# MKV56F24 register map
Vendor: Freescale Semiconductor, Inc.; Series: Kinetis_V; File version: 1.6
CPU: CM7 r0p1, little endian, no MPU, FPU, VTOR, 4 interrupt priority bits
Registers are 32-bit, read-write, reset 0x0 unless marked. A register's access mark holds for its fields unless they carry their own. Offsets are from the block's base; [hi:lo] are bit positions; {n}, {i} and the like mark numbered series; 'fields as' and 'values as' point back to an identical list.

## SysTick — System timer
Base 0xE000E010; register names take the prefix SYST_
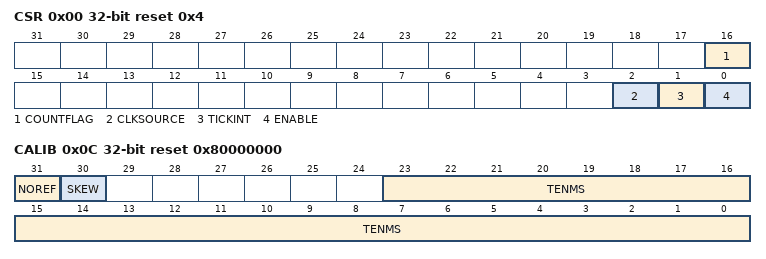
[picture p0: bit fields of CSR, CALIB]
0x00 CSR reset 0x4 — SysTick Control and Status Register
  [16] COUNTFLAG
  [2] CLKSOURCE
    0=external clock; 1=processor clock
  [1] TICKINT
    0=counting down to 0 does not assert the SysTick exception request; 1=counting down to 0 asserts the SysTick exception request
  [0] ENABLE
    0=counter disabled; 1=counter enabled
0x04 RVR — SysTick Reload Value Register
  [23:0] RELOAD — Value to load into the SysTick Current Value Register when the counter reaches 0
0x08 CVR — SysTick Current Value Register
  [23:0] CURRENT — Current value at the time the register is accessed
0x0C CALIB ro reset 0x80000000 — SysTick Calibration Value Register
  [31] NOREF
    0=The reference clock is provided; 1=The reference clock is not provided
  [30] SKEW
    0=10ms calibration value is exact; 1=10ms calibration value is inexact, because of the clock frequency
  [23:0] TENMS — Reload value to use for 10ms timing

## MCM — Core Platform Miscellaneous Control Module
Base 0xE0080000; register names take the prefix MCM_
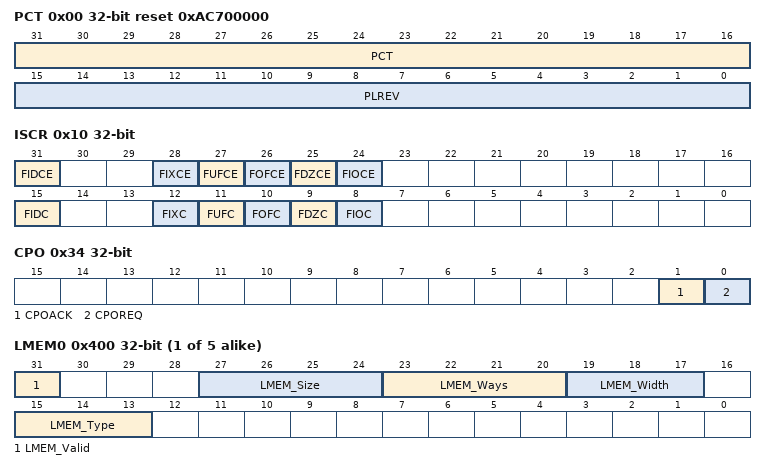
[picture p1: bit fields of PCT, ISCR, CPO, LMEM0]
0x00 PCT ro reset 0xAC700000 — Processor core type
  [31:16] PCT — This MCM design supports the ARM Cortex M7 core.
  [15:0] PLREV — Platform revision
0x0C CR — Control Register
  [27] AHBSPRI — AHB Slave Interface Priority
    0=SW accesses take priority over AHBS accesses; 1=AHBS accesses take priority over SW accesses
0x10 ISCR — Interrupt Status and Control Register
  [31] FIDCE — FPU input denormal interrupt enable
    0=Disable interrupt; 1=Enable interrupt
  [28] FIXCE — FPU inexact interrupt enable
    0=Disable interrupt; 1=Enable interrupt
  [27] FUFCE — FPU underflow interrupt enable
    0=Disable interrupt; 1=Enable interrupt
  [26] FOFCE — FPU overflow interrupt enable
    0=Disable interrupt; 1=Enable interrupt
  [25] FDZCE — FPU divide-by-zero interrupt enable
    0=Disable interrupt; 1=Enable interrupt
  [24] FIOCE — FPU invalid operation interrupt enable
    0=Disable interrupt; 1=Enable interrupt
  [15] FIDC ro — FPU input denormal interrupt status
    0=No interrupt; 1=Interrupt has occured
  [12] FIXC ro — FPU inexact interrupt status
    0=No interrupt; 1=Interrupt has occured
  [11] FUFC ro — FPU underflow interrupt status
    0=No interrupt; 1=Interrupt has occurred
  [10] FOFC ro — FPU overflow interrupt status
    0=No interrupt; 1=Interrupt has occurred
  [9] FDZC ro — FPU divide-by-zero interrupt status
    0=No interrupt; 1=Interrupt has occurred
  [8] FIOC ro — FPU invalid operation interrupt status
    0=No interrupt; 1=Interrupt has occurred
0x34 CPO — Compute Only Operation Control Register
  [1] CPOACK ro — Compute Only Operation acknowledge
    0=Compute only operation entry has not completed or compute only operation exit has completed; 1=Compute only operation entry has completed or compute only operation exit has not completed
  [0] CPOREQ — Compute Only Operation request
    0=Request is cleared; 1=Request Compute Only Operation
{0x400+4i} LMEM{i} (i=0..4) ro — Local Memory General Descriptor Register
  [31] LMEM_Valid — Defines whether the local memory is present
    0=Local memory not present; 1=Local memory present
  [27:24] LMEM_Size — Defines the local memory size
    4=8KB; 5=16KB; 7=64KB
  [23:20] LMEM_Ways — Defines the ways of set associative
    2=2-way set associative; 4=4-way set associative
  [19:17] LMEM_Width — Defines the local memory bit width
    2=32-bits; 3=64-bits
  [15:13] LMEM_Type — Defines the type of local memory
    0=ITCM (Instruction Tightly Coupled Memory); 1=DTCM (Data Tightly Coupled Memory); 2=Instruction Cache; 3=Data Cache

## CAU — Memory Mapped Cryptographic Acceleration Unit (MMCAU)
Base 0xE0081000
{0x0+4i} CAU_DIRECT{i} wo (i=0..15) — Direct access register {i}
  [31:0] CAU_DIRECT{i} — Direct register {i}
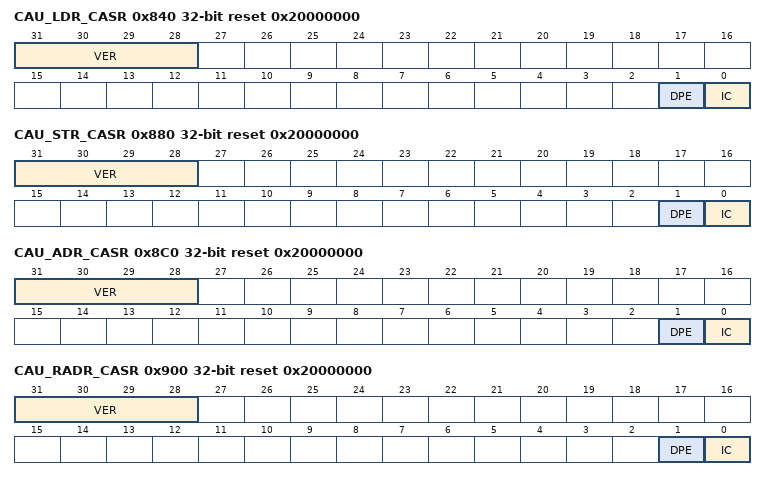
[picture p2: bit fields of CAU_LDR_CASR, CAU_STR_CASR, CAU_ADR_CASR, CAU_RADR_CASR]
0x840 CAU_LDR_CASR wo reset 0x20000000 — Status register - Load Register command
  [31:28] VER — CAU version
    1=Initial CAU version; 2=Second version, added support for SHA-256 algorithm.(This is the value on this device)
  [1] DPE
    0=No error detected; 1=DES key parity error detected
  [0] IC
    0=No illegal commands issued; 1=Illegal command issued
0x844 CAU_LDR_CAA wo — Accumulator register - Load Register command
  [31:0] ACC
{0x848+4i} CAU_LDR_CA{i} wo (i=0..8) — General Purpose Register {i} - Load Register command
0x880 CAU_STR_CASR ro reset 0x20000000 — Status register - Store Register command
  fields as CAU_LDR_CASR
0x884 CAU_STR_CAA ro — Accumulator register - Store Register command
  [31:0] ACC
{0x888+4i} CAU_STR_CA{i} ro (i=0..8) — General Purpose Register {i} - Store Register command
0x8C0 CAU_ADR_CASR wo reset 0x20000000 — Status register - Add Register command
  fields as CAU_LDR_CASR
0x8C4 CAU_ADR_CAA wo — Accumulator register - Add to register command
  [31:0] ACC
{0x8C8+4i} CAU_ADR_CA{i} wo (i=0..8) — General Purpose Register {i} - Add to register command
0x900 CAU_RADR_CASR wo reset 0x20000000 — Status register - Reverse and Add to Register command
  fields as CAU_LDR_CASR
0x904 CAU_RADR_CAA wo — Accumulator register - Reverse and Add to Register command
  [31:0] ACC
{0x908+4i} CAU_RADR_CA{i} wo (i=0..8) — General Purpose Register {i} - Reverse and Add to Register command
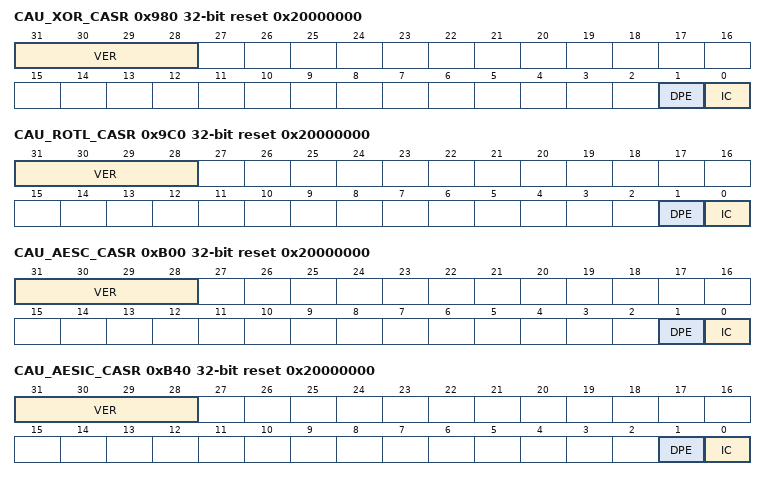
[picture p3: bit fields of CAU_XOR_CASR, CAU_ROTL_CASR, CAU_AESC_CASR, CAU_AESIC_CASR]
0x980 CAU_XOR_CASR wo reset 0x20000000 — Status register - Exclusive Or command
  fields as CAU_LDR_CASR
0x984 CAU_XOR_CAA wo — Accumulator register - Exclusive Or command
  [31:0] ACC
{0x988+4i} CAU_XOR_CA{i} wo (i=0..8) — General Purpose Register {i} - Exclusive Or command
0x9C0 CAU_ROTL_CASR wo reset 0x20000000 — Status register - Rotate Left command
  fields as CAU_LDR_CASR
0x9C4 CAU_ROTL_CAA wo — Accumulator register - Rotate Left command
  [31:0] ACC
{0x9C8+4i} CAU_ROTL_CA{i} wo (i=0..8) — General Purpose Register {i} - Rotate Left command
0xB00 CAU_AESC_CASR wo reset 0x20000000 — Status register - AES Column Operation command
  fields as CAU_LDR_CASR
0xB04 CAU_AESC_CAA wo — Accumulator register - AES Column Operation command
  [31:0] ACC
{0xB08+4i} CAU_AESC_CA{i} wo (i=0..8) — General Purpose Register {i} - AES Column Operation command
0xB40 CAU_AESIC_CASR wo reset 0x20000000 — Status register - AES Inverse Column Operation command
  fields as CAU_LDR_CASR
0xB44 CAU_AESIC_CAA wo — Accumulator register - AES Inverse Column Operation command
  [31:0] ACC
{0xB48+4i} CAU_AESIC_CA{i} wo (i=0..8) — General Purpose Register {i} - AES Inverse Column Operation command
